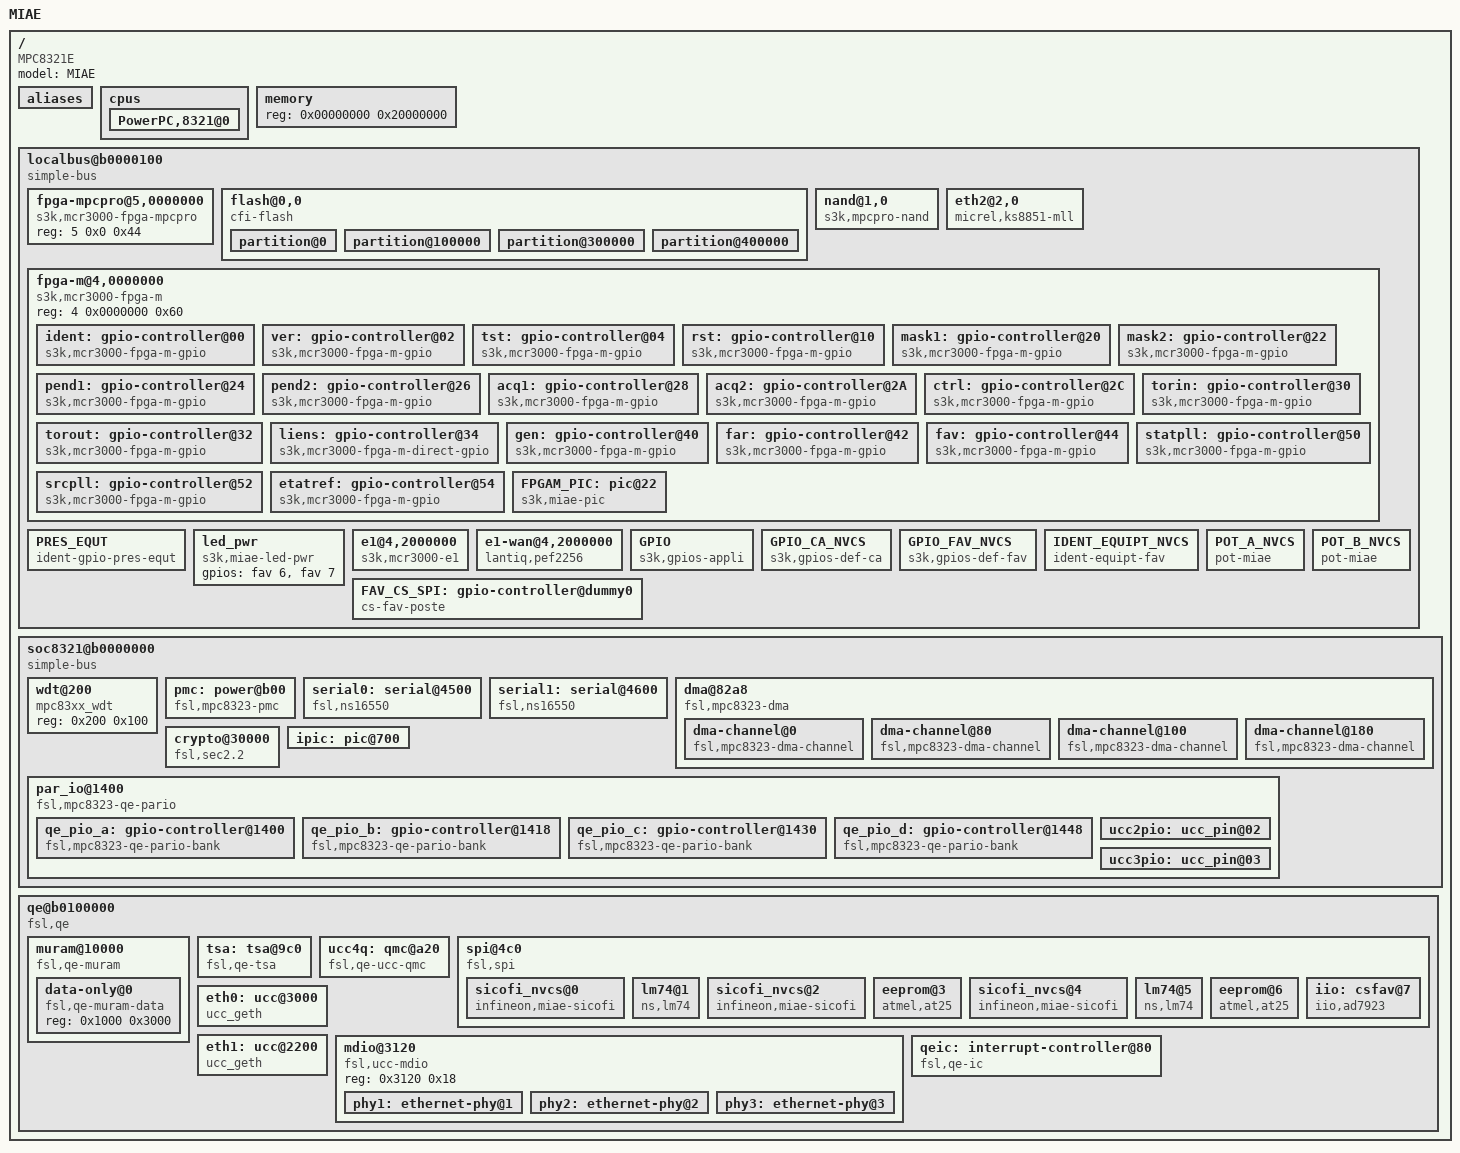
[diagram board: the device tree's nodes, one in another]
/*
 * MPC8321E MIA ethernet Device Tree Source
 * FIXME : 
 * Copyright 2007 Freescale Semiconductor Inc.
 *
 * This program is free software; you can redistribute  it and/or modify it
 * under  the terms of  the GNU General  Public License as published by the
 * Free Software Foundation;  either version 2 of the  License, or (at your
 * option) any later version.
 */

/dts-v1/;

/ {
	model = "MIAE";
	compatible = "MPC8321E", "MPC8323ERDB", "MPC832xRDB", "MPC83xxRDB", "fsl,base", "fsl,mpcpro";
	#address-cells = <1>;
	#size-cells = <1>;

	aliases {
		ethernet0 = &eth1;
		ethernet1 = &eth0;
		serial0 = &serial0;
		serial1 = &serial1;
	};

	cpus {
		#address-cells = <1>;
		#size-cells = <0>;

		PowerPC,8321@0 {
			device_type = "cpu";
			reg = <0x0>;
			d-cache-line-size = <0x20>;	// 32 bytes
			i-cache-line-size = <0x20>;	// 32 bytes
			d-cache-size = <16384>;	// L1, 16K
			i-cache-size = <16384>;	// L1, 16K
			timebase-frequency = <0>;
			bus-frequency = <0>;
			clock-frequency = <0>;
		};
	};

	memory {
		device_type = "memory";
		reg = <0x00000000 0x20000000>;
	};

	localbus@b0000100 {
		#address-cells = <2>;
		#size-cells = <1>;
		device_type = "soc";
		compatible = "simple-bus";
		ranges = <0 0x0 0x40000000 0x04000000	// Boot Flash
			  1 0x0 0xa0000000 0x00008000	// Nand Flash
			  2 0x0 0x92000000 0x00008000	// Eth Face avant
			  3 0x0 0x83400000 0x00010000	// DPRAM (DSP)
			  4 0x0 0x80000000 0x10000000	// Periphs
			  5 0x0 0x90000000 0x10000000	// FPGA-MPCPRO
			  6 0x0 0x81800000 0x00008000	// mezzanine
			  7 0x0 0x80800000 0x00008000>;	// DSP
		reg = <0xb0000000 0x00000200>;
		bus-frequency = <0>;

		fpga-mpcpro@5,0000000 {
			#address-cells = <1>;
			#size-cells = <1>;
			compatible = "s3k,mcr3000-fpga-mpcpro";
			reg = <5 0x0 0x44>;
		};

		flash@0,0 {
			#address-cells = <1>;
			#size-cells = <1>;
			compatible = "cfi-flash";
			reg = <0x0 0x00000000 0x4000000>;
			bank-width = <2>;
			device-width = <2>;
			partition@0 {
				label = "boot";
				reg = <0x0 0x100000>;
			};
			partition@100000 {
				label = "other u-boot";
				reg = <0x100000 0x200000>;
			};
			partition@300000 {
				label = "dtb";
				reg = <0x300000 0x100000>;
			};
			partition@400000 {
				label = "kernel";
				reg = <0x400000 0x400000>;
			};
		};

		nand@1,0 {
			compatible = "s3k,mpcpro-nand";
			reg = <1 0x0 0x01>;
			#address-cells = <1>;
			#size-cells = <1>;
			gpios = <&qe_pio_c 24 1 	// RDY
				 0			// nCE, we use chip select
				 &qe_pio_c 26 1		// ALE
				 &qe_pio_c 25 1		// CLE
				 0>;			// nwp
			//partition@0 {
			//	label = "mpcpro-nand";
			//	reg = <0x0 0x4000>;
			//};
		};

		eth2@2,0 {
			compatible = "micrel,ks8851-mll";
			reg =  <2 0x00 0xff
				2 0x100 0xff>;
			interrupts = <21 0x8>;
			interrupt-parent = <&ipic>;
		};

		fpga-m@4,0000000 { // Driver LDB (deviendra peut etre obsolete)
			#address-cells = <1>;
			#size-cells = <1>;
			compatible = "s3k,mcr3000-fpga-m";
			reg = <4 0x0000000 0x60>;
			ranges = <0 4 0x0000000 0x60>;
			ident: gpio-controller@00 {
				#gpio-cells = <2>;
				compatible = "s3k,mcr3000-fpga-m-gpio";
				reg = <0x00 2>;
				gpio-controller;
			};
			ver: gpio-controller@02 {
				#gpio-cells = <2>;
				compatible = "s3k,mcr3000-fpga-m-gpio";
				reg = <0x02 2>;
				gpio-controller;
			};
			tst: gpio-controller@04 {
				#gpio-cells = <2>;
				compatible = "s3k,mcr3000-fpga-m-gpio";
				reg = <0x04 2>;
				gpio-controller;
			};
			rst: gpio-controller@10 {
				#gpio-cells = <2>;
				compatible = "s3k,mcr3000-fpga-m-gpio";
				reg = <0x10 2>;
				gpio-controller;
			};
			mask1: gpio-controller@20 {
				#gpio-cells = <2>;
				compatible = "s3k,mcr3000-fpga-m-gpio";
				reg = <0x20 2>;
				gpio-controller;
			};
			mask2: gpio-controller@22 {
				#gpio-cells = <2>;
				compatible = "s3k,mcr3000-fpga-m-gpio";
				reg = <0x22 2>;
				gpio-controller;
			};
			pend1: gpio-controller@24 {
				#gpio-cells = <2>;
				compatible = "s3k,mcr3000-fpga-m-gpio";
				reg = <0x24 2>;
				gpio-controller;
			};
			pend2: gpio-controller@26 {
				#gpio-cells = <2>;
				compatible = "s3k,mcr3000-fpga-m-gpio";
				reg = <0x26 2>;
				gpio-controller;
			};
			acq1: gpio-controller@28 {
				#gpio-cells = <2>;
				compatible = "s3k,mcr3000-fpga-m-gpio";
				reg = <0x28 2>;
				gpio-controller;
			};
			acq2: gpio-controller@2A {
				#gpio-cells = <2>;
				compatible = "s3k,mcr3000-fpga-m-gpio";
				reg = <0x2A 2>;
				gpio-controller;
			};
			ctrl: gpio-controller@2C {
				#gpio-cells = <2>;
				compatible = "s3k,mcr3000-fpga-m-gpio";
				reg = <0x2C 2>;
				gpio-controller;
			};
			torin: gpio-controller@30 {
				#gpio-cells = <2>;
				compatible = "s3k,mcr3000-fpga-m-gpio";
				reg = <0x30 2>;
				interrupts = <255 255 255 255 255 5 6 7 8 9 10 11 12 13 14 15>;
				interrupt-parent = <&FPGAM_PIC>;
				gpio-controller;
			};
			torout: gpio-controller@32 {
				#gpio-cells = <2>;
				compatible = "s3k,mcr3000-fpga-m-gpio";
				reg = <0x32 2>;
				gpio-controller;
			};
			liens: gpio-controller@34 {
				#gpio-cells = <2>;
				compatible = "s3k,mcr3000-fpga-m-direct-gpio";
				reg = <0x34 2>;
				gpio-controller;
			};
			gen: gpio-controller@40 {
				#gpio-cells = <2>;
				compatible = "s3k,mcr3000-fpga-m-gpio";
				reg = <0x40 2>;
				gpio-controller;
			};
			far: gpio-controller@42 {
				#gpio-cells = <2>;
				compatible = "s3k,mcr3000-fpga-m-gpio";
				reg = <0x42 2>;
				interrupts = <255 255 255 255 255 255 255 255 255 255 255 0 28 30 29 31>;
				interrupt-parent = <&FPGAM_PIC>;
				gpio-controller;
			};
			fav: gpio-controller@44 {
				#gpio-cells = <2>;
				compatible = "s3k,mcr3000-fpga-m-gpio";
				reg = <0x44 2>;
				interrupts = <255 255 255 255 255 255 255 255 17 25 19 27 16 24 18 26>;
				interrupt-parent = <&FPGAM_PIC>;
				gpio-controller;
			};
			statpll: gpio-controller@50 {
				#gpio-cells = <2>;
				compatible = "s3k,mcr3000-fpga-m-gpio";
				reg = <0x50 2>;
				gpio-controller;
			};
			srcpll: gpio-controller@52 {
				#gpio-cells = <2>;
				compatible = "s3k,mcr3000-fpga-m-gpio";
				reg = <0x52 2>;
				gpio-controller;
			};
			etatref: gpio-controller@54 {
				#gpio-cells = <2>;
				compatible = "s3k,mcr3000-fpga-m-gpio";
				reg = <0x54 2>;
				gpio-controller;
			};
			FPGAM_PIC: pic@22 {
				interrupt-controller;
				#address-cells = <0>;
				#interrupt-cells = <1>;
				interrupts = <19 0>;
				interrupt-parent = <&ipic>;
				reg = <0x00 0x60>;	/* Mappage registres FPGAM */
				compatible = "s3k,miae-pic";
			};
		};

		PRES_EQUT {
			compatible = "ident-gpio-pres-equt";
			interrupts = <17 19 16 18>;	/* Equipt 1 et 2 */
			interrupt-parent = <&FPGAM_PIC>;
			reg = <4 0x44 2>;
			gpios = <&fav   8 1	/* Presence µCasque1 */
				&fav   10 1	/* Presence µMain1 */
				&fav   12 1	/* Presence µCasque2 */
				&fav   14 1>;	/* Presence µMain2 */
		};

		led_pwr {
			compatible = "s3k,miae-led-pwr";
			gpios = <&fav 6 2	/* led multi verte */
				 &fav 7 0>;	/* led multi rouge */
		};

		e1@4,2000000 {
			#address-cells = <1>;
			#size-cells = <1>;
			compatible = "s3k,mcr3000-e1";
			reg = <4 0x2000000 0xFF>;
			interrupts = <20 0>;
			interrupt-parent = <&ipic>;
		};
		
		e1-wan@4,2000000 {
			#address-cells = <1>;
			#size-cells = <1>;
			compatible = "lantiq,pef2256";
			reg = <4 0x2000000 0xFF>;
			data-rate = <4>;
			interrupts = <20 0>;
			interrupt-parent = <&ipic>;
		};
		
		GPIO {
			/* 0 = sortie initialisee active */
			/* 1 = entree */
			/* 2 = sortie initialisee inactive */
			compatible = "s3k,gpios-appli";
			reg = <4 0x42 4>;
			gpios = <&torin   15 1	// TOR in 1
				&torin    14 1	// TOR in 2
				&torin    13 1	// TOR in 3
				&torin    12 1	// TOR in 4
				&torin    11 1	// TOR in 5
				&torin    10 1	// TOR in 6
				&torin     9 1	// TOR in 7
				&torin     8 1	// TOR in 8
				&torin     7 1	// TOR in 9
				&torin     6 1	// TOR in 10
				&torin     5 1	// TOR in 11
				&torout   15 2	// TOR out 1
				&torout   14 2	// TOR out 2
				&torout   13 2	// TOR out 3
				&torout   12 2	// TOR out 4
				&torout   11 2	// TOR out 5
				&torout   10 2	// TOR out 6
				&torout    9 2	// TOR out 7
				&torout    8 2	// TOR out 8
				&far      15 1	// BP Alt
				&far      13 1	// Alternat 1
				&far      14 1	// Alternat 2
				&far      12 1	// Alternat Combine
				&far      11 1	// Presence Combine
				&fav      11 1	// Alternat µMain1
				&fav      15 1	// Alternat µMain2
				&fav       9 1	// Alternat µCasque1
				&fav      13 1>;	// Alternat µCasque2
		};

/*		GPIO_CA_CLA {
			compatible = "s3k,gpios-def-ca", "cs,mia-far";
			far-id = <0 7>;
			names = "tor_in_1",
				"tor_in_2",
				"tor_in_3",
				"tor_in_4",
				"tor_in_5",
				"tor_in_6",
				"tor_in_7",
				"tor_in_8",
				"tor_in_9",
				"tor_in_10",
				"tor_in_11",
				"tor_out_1",
				"tor_out_2",
				"tor_out_3",
				"tor_out_4",
				"tor_out_5",
				"tor_out_6",
				"tor_out_7",
				"tor_out_8",
				"alt_bp",
				"tor_in_13",		// Alternat 1
				"tor_in_14",		// Alternat 2
				"alt_ucomb",
				"pres_ucomb";
			codec = "Rec. In 1",
				"Interco In 1",
				"Rec. In 2",
				"Interco In 2",
				"Micro ITH",
				"Audio OPT 1",
				"Audio OPT 2",
				"Micro Combine",
				"Rec. Out 1",
				"Interco Out 1",
				"Rec. Out 2",
				"Interco Out 2",
				"HP ITH",
				"HP 1",
				"HP 2",
				"Ecoute Combine";
		};

		GPIO_FAV_CLA {
			compatible = "s3k,gpios-def-fav", "cs,mia-fav";
			fav-id = <7>;
			names = "alt_umain_a",
				"alt_umain_b",
				"alt_ucasque_a",
				"alt_ucasque_b";
			pres  = "pres_ucasque_a",
				"pres_umain_a",
				"pres_ucasque_b",
				"pres_umain_b";
			codec = "Micro Casque_a",
				"Micro Main_a",
				"Micro Casque_b",
				"Micro Main_b",
				"Ec. droite Casque_a",
				"Ec. gauche Casque_a",
				"Ec. droite Casque_b",
				"Ec. gauche Casque_b";
		};
*/
		GPIO_CA_NVCS {
			compatible = "s3k,gpios-def-ca", "cs,mia-far";
			far-id = <1>;
			names = "tor_in_audio_1",
				"tor_in_audio_2",
				"tor_in_audio_3",
				"tor_in_audio_4",
				"tor_in_5",
				"alt_pedale_1",
				"alt_pedale_2",
				"dec_ucomb",
				"tor_in_9",
				"tor_in_10",
				"alt_aith",
				"tor_out_audio_1",
				"tor_out_audio_2",
				"tor_out_audio_3",
				"tor_out_audio_4",
				"tor_out_5",
				"tor_out_6",
				"none",
				"none",
				"alt_bp",
				"tor_in_13",		// Alternat 1
				"tor_in_14",		// Alternat 2
				"alt_ucomb",
				"pres_ucomb";
			codec = "Audio In 1",
				"Audio In 2",
				"Audio In 3",
				"Audio In 4",
				"Micro ITH",
				"Audio OPT 1",
				"Audio OPT 2",
				"Micro Combine",
				"Audio Out 1",
				"Audio Out 2",
				"Audio Out 3",
				"Audio Out 4",
				"Audio Out 5",
				"HP 1",
				"HP 2",
				"Ecoute Combine";
		};

		GPIO_FAV_NVCS {
			compatible = "s3k,gpios-def-fav", "cs,mia-fav";
			fav-id = <3 5 6>;
			names = "alt_umain_a",
				"alt_umain_b",
				"alt_ucasque_a",
				"alt_ucasque_b";
			pres  = "pres_ucasque_a",
				"pres_umain_a",
				"pres_ucasque_b",
				"pres_umain_b";
			codec = "Micro Casque_a",
				"Micro Main_a",
				"Micro Casque_b",
				"Micro Main_b",
				"Ec. droite Casque_a",
				"Ec. gauche Casque_a",
				"Ec. droite Casque_b",
				"Ec. gauche Casque_b";
		};
/*
		GPIO_CA_GW {
			compatible = "s3k,gpios-def-ca", "cs,mia-far";
			far-id = <4>;
			names = "tor_in_1",
				"tor_in_2",
				"tor_in_3",
				"tor_in_4",
				"tor_in_5",
				"tor_in_6",
				"tor_in_7",
				"none",
				"none",
				"dptt",
				"pt_ct",
				"tor_out_1",
				"tor_out_2",
				"tor_out_3",
				"tor_out_4",
				"tor_out_5",
				"tor_out_6",
				"tor_out_7",
				"cgc",
				"none",
				"none",
				"none",
				"none",
				"none";
			codec = "Audio In 1",
				"Audio In 2",
				"Audio In 3",
				"Audio In 4",
				"Audio In 5",
				"Audio In 6",
				"Audio In 7",
				"Audio In 8",
				"Audio Out 1",
				"Audio Out 2",
				"Audio Out 3",
				"Audio Out 4",
				"not used",
				"not used",
				"not used",
				"not used";
		};

		GPIO_FAV_GW {
			compatible = "s3k,gpios-def-fav", "cs,mia-fav";
			fav-id = <4>;
			names = "none",
				"none",
				"none",
				"none";
			pres  = "none",
				"none",
				"none",
				"none";
			codec = "Micro Casque_a",
				"not used",
				"not used",
				"not used",
				"Ec. droite Casque_a",
				"not used",
				"not used",
				"not used";
		};
*/		
		IDENT_EQUIPT_NVCS {
			compatible = "ident-equipt-fav", "cs,mia-fav";
			fav-id = <3 5 6>;
			infos = "22",	/* nombre d'équipements possibles */
				/* bornes min et max, niveaux in et out en dB, croissement TS, type casque */
				"0",	"340",	"-27",	"-10",	"no",	"yes",	/* equipement 1 */
				"341",	"420",	"-27",	"-10",	"no",	"yes",	/* equipement 2 */
				"421",	"502",	"-27",	"-10",	"no",	"yes",	/* equipement 3 */
				"503",	"578",	"-27",	"-10",	"no",	"yes",	/* equipement 4 */
				"579",	"682",	"-27",	"-10",	"no",	"yes",	/* equipement 5 */
				"683",	"804",	"-27",	"-10",	"no",	"yes",	/* equipement 6 */
				"805",	"908",	"-7",	"-17",	"yes",	"yes",	/* equipement 7 */
				"909",	"1016",	"-27",	"-10",	"no",	"yes",	/* equipement 8 */
				"1017",	"1120",	"-27",	"-10",	"no",	"yes",	/* equipement 9 */
				"1121",	"1232",	"-27",	"-10",	"no",	"yes",	/* equipement 10 */
				"1233",	"1392",	"-27",	"-10",	"no",	"yes",	/* equipement 11 */
				"1393",	"1523",	"-23",	"-1",	"no",	"yes",	/* equipement 12 */
				"1524",	"1664",	"-27",	"-10",	"no",	"yes",	/* equipement 13 */
				"1665",	"1786",	"-27",	"-10",	"no",	"yes",	/* equipement 14 */
				"1787",	"1954",	"-27",	"-10",	"no",	"yes",	/* equipement 15 */
				"1955",	"2194",	"-27",	"-10",	"no",	"yes",	/* equipement 16 */
				"2195",	"2396",	"-27",	"-10",	"no",	"yes",	/* equipement 17 */
				"2397",	"2556",	"-27",	"-10",	"no",	"yes",	/* equipement 18 */
				"2557",	"2738",	"-27",	"-10",	"no",	"yes",	/* equipement 19 */
				"2739",	"2966",	"-27",	"-10",	"no",	"yes",	/* equipement 20 */
				"2967",	"3156",	"-11",	"-10",	"no",	"no",	/* equipement 21 */
				"3157",	"4095",	"-27",	"-10",	"no",	"yes";	/* sans equipement */
		};

		FAV_CS_SPI: gpio-controller@dummy0 {
			#gpio-cells = <2>;
			compatible = "cs-fav-poste";
			gpio-controller;
			reg = <4 0x44 2>;
			gpios = <&fav 5 1	/* CS FAV */
				 &fav 4 1	/* CS Ident equipement */
				 &fav 3 1>;	/* CS FPGA */
		};
		
		POT_A_NVCS {
			compatible = "pot-miae", "cs,mia-fav";
			fav-id = <5 6>;
			user-name = "pot_a";
			dev-name = "ad7923";
			io-channels = <&iio 0>;
			io-channel-names = "channel_0";
			dev-channel = "channel_0";
		};
		POT_B_NVCS {
			compatible = "pot-miae", "cs,mia-fav";
			fav-id = <5 6>;
			user-name = "pot_b";
			dev-name = "ad7923";
			io-channels = <&iio 1>;
			io-channel-names = "channel_1";
			dev-channel = "channel_1";
		};
		
/*		POT_A_PO {
			compatible = "pot-miae", "cs,mia-fav";
			fav-id = <3>;
			user-name = "pot_a";
			dev-name = "none";
			dev-channel = "channel_0";
		};
		POT_B_PO {
			compatible = "pot-miae", "cs,mia-fav";
			fav-id = <3>;
			user-name = "pot_b";
			dev-name = "none";
			dev-channel = "channel_1";
		};
		POT_C_PO {
			compatible = "pot-miae", "cs,mia-fav";
			fav-id = <3>;
			user-name = "pot_c";
			dev-name = "none";
			dev-channel = "channel_2";
		};
		POT_D_PO {
			compatible = "pot-miae", "cs,mia-fav";
			fav-id = <3>;
			user-name = "pot_d";
			dev-name = "none";
			dev-channel = "channel_3";
		};
*/	};

	soc8321@b0000000 {
		#address-cells = <1>;
		#size-cells = <1>;
		device_type = "soc";
		compatible = "simple-bus";
		ranges = <0x0 0xb0000000 0x00100000>;
		reg = <0xb0000000 0x00000200>;
		bus-frequency = <0>;
		
		wdt@200 {
			device_type = "watchdog";
			compatible = "mpc83xx_wdt";
			reg = <0x200 0x100>;
		};

		pmc: power@b00 {
			compatible = "fsl,mpc8323-pmc", "fsl,mpc8349-pmc";
			reg = <0xb00 0x100 0xa00 0x100>;
			interrupts = <80 0x8>;
			interrupt-parent = <&ipic>;
		};

		serial0: serial@4500 {
			cell-index = <0>;
			device_type = "serial";
			compatible = "fsl,ns16550", "ns16550";
			reg = <0x4500 0x100>;
			clock-frequency = <0>;
			interrupts = <9 0x8>;
			interrupt-parent = <&ipic>;
		};

		serial1: serial@4600 {
			cell-index = <1>;
			device_type = "serial";
			compatible = "fsl,ns16550", "ns16550";
			reg = <0x4600 0x100>;
			clock-frequency = <0>;
			interrupts = <10 0x8>;
			interrupt-parent = <&ipic>;
		};

		dma@82a8 {
			#address-cells = <1>;
			#size-cells = <1>;
			compatible = "fsl,mpc8323-dma", "fsl,elo-dma";
			reg = <0x82a8 4>;
			ranges = <0 0x8100 0x1a8>;
			interrupt-parent = <&ipic>;
			interrupts = <71 8>;
			cell-index = <0>;
			dma-channel@0 {
				compatible = "fsl,mpc8323-dma-channel", "fsl,elo-dma-channel";
				reg = <0 0x80>;
				cell-index = <0>;
				interrupt-parent = <&ipic>;
				interrupts = <71 8>;
			};
			dma-channel@80 {
				compatible = "fsl,mpc8323-dma-channel", "fsl,elo-dma-channel";
				reg = <0x80 0x80>;
				cell-index = <1>;
				interrupt-parent = <&ipic>;
				interrupts = <71 8>;
			};
			dma-channel@100 {
				compatible = "fsl,mpc8323-dma-channel", "fsl,elo-dma-channel";
				reg = <0x100 0x80>;
				cell-index = <2>;
				interrupt-parent = <&ipic>;
				interrupts = <71 8>;
			};
			dma-channel@180 {
				compatible = "fsl,mpc8323-dma-channel", "fsl,elo-dma-channel";
				reg = <0x180 0x28>;
				cell-index = <3>;
				interrupt-parent = <&ipic>;
				interrupts = <71 8>;
			};
		};

		crypto@30000 {
			compatible = "fsl,sec2.2", "fsl,sec2.1", "fsl,sec2.0";
			reg = <0x30000 0x10000>;
			interrupts = <11 0x8>;
			interrupt-parent = <&ipic>;
			fsl,num-channels = <1>;
			fsl,channel-fifo-len = <24>;
			fsl,exec-units-mask = <0x4c>;
			fsl,descriptor-types-mask = <0x0122003f>;
			sleep = <&pmc 0x03000000>;
		};

		ipic:pic@700 {
			interrupt-controller;
			#address-cells = <0>;
			#interrupt-cells = <2>;
			reg = <0x700 0x100>;
			device_type = "ipic";
		};

		par_io@1400 {
			#address-cells = <1>;
			#size-cells = <1>;
			reg = <0x1400 0x100>;
			ranges = < 0 0 0xb0001400 0x18
				   1 0 0xb0001418 0x18
				   2 0 0xb0001430 0x18
				   3 0 0xb0001448 0x18>;
			compatible = "fsl,mpc8323-qe-pario";
			device_type = "par_io";
			num-ports = <7>;

			qe_pio_a: gpio-controller@1400 {
				#gpio-cells = <2>;
				compatible = "fsl,mpc8323-qe-pario-bank";
				reg = <0x1400 0x18>;
				gpio-controller;
			};

			qe_pio_b: gpio-controller@1418 {
				#gpio-cells = <2>;
				compatible = "fsl,mpc8323-qe-pario-bank";
				reg = <0x1418 0x18>;
				gpio-controller;
			};

			qe_pio_c: gpio-controller@1430 {
				#gpio-cells = <2>;
				compatible = "fsl,mpc8323-qe-pario-bank";
				reg = <0x1430 0x18>;
				gpio-controller;
			};

			qe_pio_d: gpio-controller@1448 {
				#gpio-cells = <2>;
				compatible = "fsl,mpc8323-qe-pario-bank";
				reg = <0x1448 0x18>;
				gpio-controller;
			};

			ucc2pio:ucc_pin@02 {
				pio-map = <
			/* port  pin  dir  open_drain  assignment  has_irq */
				3  4  3  0  2  0 	/* MDIO */
				3  5  1  0  2  0 	/* MDC */

				0 18  1  0  1  0	/* R1_TXD0 */
				0 19  1  0  1  0	/* R1_TXD1 */
				0 22  2  0  1  0	/* R1_RXD0 */
				0 23  2  0  1  0	/* R1_RXD1 */
				0 30  1  0  1  0	/* R1_TXEN */
				0 28  2  0  1  0	/* R1_CRS_DV */
				0 26  2  0  1  0	/* R1_RXER */
				3 10  2  0  3  0>;	/* R1_REF_CLK */
			};
			ucc3pio:ucc_pin@03 {
				pio-map = <
			/* port  pin  dir  open_drain  assignment  has_irq */
				1  0  1  0  1  0	/* R2_TXD0 */
				1  1  1  0  1  0	/* R2_TXD1 */
				1  4  2  0  1  0	/* R2_RXD0 */
				1  5  2  0  1  0	/* R2_RXD1 */
				1 12  1  0  1  0	/* R2_TXEN */
				1 10  2  0  1  0	/* R2_CRS_DV */
				1  8  2  0  1  0	/* R2_RXER */
				1 14  2  0  1  0>;	/* R2_REF_CLK */
			};
		};
	};

	qe@b0100000 {
		#address-cells = <1>;
		#size-cells = <1>;
		device_type = "qe";
		compatible = "fsl,qe";
		ranges = <0x0 0xb0100000 0x00100000>;
		reg = <0xb0100000 0x480>;
		brg-frequency = <0>;
		bus-frequency = <198000000>;
		fsl,qe-num-riscs = <1>;
		fsl,qe-num-snums = <28>;

		muram@10000 {
 			#address-cells = <1>;
 			#size-cells = <1>;
			compatible = "fsl,qe-muram", "fsl,cpm-muram";
			ranges = <0x0 0x00010000 0x00004000>;

			/* conserver les 4 premiers Kbytes pour QMC */
			data-only@0 {
				compatible = "fsl,qe-muram-data",
					     "fsl,cpm-muram-data";
				reg = <0x1000 0x3000>;
			};
		};

		tsa: tsa@9c0 {
			compatible = "fsl,qe-tsa";
			reg = <0x9c0 0x1>;	/* necessaire mais non utilise */
			/* parametres possible : none, UCC4 */
			ucc_qmc_miae = "UCC4";
			/* vitesse bus numerique 4 ou 8 MHz */
			data_rate = <4>;
		};

		ucc4q: qmc@a20 {
			device_type = "qmc";
			compatible = "fsl,qe-ucc-qmc";
			cell-index = <4>;	/* The UCC number, 1-7*/
			reg = <0x3200 0x200 0x10000 0x1000>;
			interrupts = <35>;
			interrupt-parent = <&qeic>;
			clock-name = "clk1";
		};

		spi@4c0 {
			#address-cells = <1>;
			#size-cells = <0>;
			cell-index = <0>;
			compatible = "fsl,spi";
			reg = <0x4c0 0x40>;
			interrupts = <2>;
			interrupt-parent = <&qeic>;
			mode = "qe";
			     	/* port     pin cs-high */
			gpios =  <&qe_pio_b 16   1	/* SICOFI 1 */
				  &qe_pio_c  5   1	/* TEMP carte base */
				  &qe_pio_c 28   1	/* SICOFI 2 */
				  &qe_pio_d  3   1	/* EEPROM MPCPRO */
				  &qe_pio_c 23   1	/* SICOFI 3 */
				  &qe_pio_c  3   1	/* TEMP MPCPRO */
				  &qe_pio_c  2   1	/* EEPROM carte base */
				  &FAV_CS_SPI 0  1	/* FAV SPI */
				  &FAV_CS_SPI 2  1>;	/* FAV POSTE FPGA */

/*			sicofi@0 {
				compatible = "infineon,miae-sicofi", "cs,mia-far";
				far-id = <0 2 3 4 5 6 7>;
				spi-max-frequency = <1000000>;
				reg = <0>;
				spi-cs-high;
				spi-cpha;
				spi-troll;
				name_codec = "codec_1";
				analog_in = "-2dB -2dB -2dB -2dB";
				analog_out = "6dB 6dB 6dB 6dB";
				niveau_in = "-10dB -10dB -10dB -10dB";
				niveau_out = "-10dB -10dB -10dB -10dB";
			};
*/			sicofi_nvcs@0 {
				compatible = "infineon,miae-sicofi", "cs,mia-far";
				far-id = <1>;
				spi-max-frequency = <1000000>;
				reg = <0>;
				spi-cs-high;
				spi-cpha;
				spi-troll;
				name_codec = "codec_1";
				analog_in = "-2dB -2dB -2dB -2dB";
				analog_out = "0dB 0dB 0dB 0dB";
				niveau_in = "-10dB -10dB -10dB -10dB";
				niveau_out = "-10dB -10dB -10dB -10dB";
			};
			lm74@1 {
				compatible = "ns,lm74";
				spi-max-frequency = <1000000>;
				reg = <1>;
				spi-cs-high;
			};
//			sicofi@2 {
//				compatible = "infineon,miae-sicofi", "cs,mia-far";
//				far-id = <0 2 3 5 6 7>;
//				spi-max-frequency = <1000000>;
//				reg = <2>;
//				spi-cs-high;
//				spi-cpha;
//				spi-troll;
//				name_codec = "codec_2";
//				analog_in = "-2dB 0dB 0dB 12dB";
//				analog_out = "3dB 3dB 3dB 4,5dB";
//				niveau_in = "-10dB -10dB -10dB -31dB";
//				niveau_out = "-10dB -10dB -10dB -10dB";
//			};
			sicofi_nvcs@2 {
				compatible = "infineon,miae-sicofi", "cs,mia-far";
				far-id = <1>;
				spi-max-frequency = <1000000>;
				reg = <2>;
				spi-cs-high;
				spi-cpha;
				spi-troll;
				name_codec = "codec_2";
				analog_in = "-2dB 0dB 0dB 18dB";
				analog_out = "6dB 3dB 3dB 4,5dB";
				niveau_in = "-10dB -10dB -10dB -37dB";
				niveau_out = "-10dB -10dB -10dB -10dB";
			};
//			sicofi_gw@2 {
//				compatible = "infineon,miae-sicofi", "cs,mia-far";
//				far-id = <4>;
//				spi-max-frequency = <1000000>;
//				reg = <2>;
//				spi-cs-high;
//				spi-cpha;
//				spi-troll;
//				name_codec = "codec_2";
//				analog_in = "-3dB -3dB -3dB -3dB";
//				analog_out = "3dB 3dB 3dB 3dB";
//				niveau_in = "-10dB -10dB -10dB -10dB";
//				niveau_out = "-10dB -10dB -10dB -10dB";
//			};
			eeprom@3 {
				compatible = "atmel,at25", "cs,eeprom";
				spi-max-frequency = <1000000>;
				reg = <3>;
				spi-cs-high;
				at25,byte-len = <1024>;
				at25,addr-mode = <2>;
				at25,page-size = <32>;
			};
//			sicofi@4 {
//				compatible = "infineon,miae-sicofi", "cs,mia-fav";
//				fav-id = <0 1 2 4 7>;
//				spi-max-frequency = <1000000>;
//				reg = <4>;
//				spi-cs-high;
//				spi-cpha;
//				spi-troll;
//				name_codec = "codec_3";
//				analog_in = "12dB -7dB 12dB -7dB";
//				analog_out = "6dB 6dB 6dB 6dB";
//				niveau_in = "-27dB -8dB -27dB -8dB";
//				niveau_out = "-10dB -10dB -10dB -10dB";
//			};
			sicofi_nvcs@4 {
				compatible = "infineon,miae-sicofi", "cs,mia-fav";
				fav-id = <5 6>;
				spi-max-frequency = <1000000>;
				reg = <4>;
				spi-cs-high;
				spi-cpha;
				spi-troll;
				name_codec = "codec_3";
				analog_in = "12dB -7dB 12dB -7dB";
				analog_out = "6dB 6dB 6dB 6dB";
				niveau_in = "-27dB -8dB -27dB -8dB";
				niveau_out = "-10dB -10dB -10dB -10dB";
				io-channels = <&iio 2>, <&iio 3>;
				iio-name = "ad7923";
				io-channel-names = "channel_2", "channel_3";
				iio-channel = "channel_2", "channel_3";
			};
//			sicofi_postes@4 {
//				compatible = "infineon,miae-sicofi", "cs,mia-fav";
//				fav-id = <3>;
//				spi-max-frequency = <1000000>;
//				reg = <4>;
//				spi-cs-high;
//				spi-cpha;
//				spi-troll;
//				name_codec = "codec_3";
//				analog_in = "12dB -7dB 12dB -7dB";
//				analog_out = "6dB 6dB 6dB 6dB";
//				niveau_in = "-27dB -8dB -27dB -8dB";
//				niveau_out = "-10dB -10dB -10dB -10dB";
//				io-channels = <&iio 0>, <&iio 1>;
//				iio-name = "ad7923";
//				io-channel-names = "channel_0", "channel_1";
//				iio-channel = "channel_0", "channel_1";
//			};
			lm74@5 {
				compatible = "ns,lm74";
				spi-max-frequency = <1000000>;
				reg = <5>;
				spi-cs-high;
			};
			eeprom@6 {
				compatible = "atmel,at25", "cs,eeprom";
				spi-max-frequency = <1000000>;
				reg = <6>;
				spi-cs-high;
				at25,byte-len = <1024>;
				at25,addr-mode = <2>;
				at25,page-size = <32>;
			};
			iio: csfav@7 {
				compatible = "iio,ad7923", "cs,mia-fav";
				spi-max-frequency = <2000000>;
				reg = <7>;
				spi-cs-high;
				spi-cpol;
				fav-id = <3 5 6>;
				#io-channel-cells = <1>;
			};
//			gpiofav: csfavgw@7 {
//				compatible = "gpio,max7301", "cs,mia-fav";
//				spi-max-frequency = <2000000>;
//				reg = <7>;
//				spi-cs-high;
//				#gpio-cells = <2>;
//				gpio-controller;
//				fav-id = <4>;
//			};
//			csfavfpga@8 {
//				compatible = "cs,fpga-poste", "cs,mia-fav";
//				spi-max-frequency = <2000000>;
//				reg = <8>;
//				spi-cs-high;
//				fav-id = <3>;
//			};
                };

//		spi@500 {
//			cell-index = <1>;
//			compatible = "fsl,spi";
//			reg = <0x500 0x40>;
//			interrupts = <1>;
//			interrupt-parent = <&qeic>;
//			mode = "cpu";
//		};

		eth0: ucc@3000 {
			device_type = "network";
			compatible = "ucc_geth";
			cell-index = <2>;
			reg = <0x3000 0x200>;
			interrupts = <33>;
			interrupt-parent = <&qeic>;
			local-mac-address = [ 00 00 00 00 00 00 ];
			rx-clock-name = "clk17";
			tx-clock-name = "clk17";
			phy-handle = <&phy1>;
			pio-handle = <&ucc2pio>;
			phy-connection-type = "rmii";
		};

		eth1: ucc@2200 {
			device_type = "network";
			compatible = "ucc_geth";
			cell-index = <3>;
			reg = <0x2200 0x200>;
			interrupts = <34>;
			interrupt-parent = <&qeic>;
			local-mac-address = [ 00 00 00 00 00 00 ];
			rx-clock-name = "clk12";
			tx-clock-name = "clk12";
			phy-handle = <&phy3 &phy2>;
			pio-handle = <&ucc3pio>;
			phy-connection-type = "rmii";
		};

		mdio@3120 {
			#address-cells = <1>;
			#size-cells = <0>;
			reg = <0x3120 0x18>;
			compatible = "fsl,ucc-mdio";

			phy1:ethernet-phy@1 {
				interrupt-parent = <&ipic>;
				reg = <0x1>;
				device_type = "ethernet-phy";
			};
			phy2:ethernet-phy@2 {
				interrupt-parent = <&ipic>;
				reg = <0x2>;	
				device_type = "ethernet-phy";
			};
			phy3:ethernet-phy@3 {
				interrupt-parent = <&ipic>;
				reg = <0x3>;	
				device_type = "ethernet-phy";
			};
		};

		qeic:interrupt-controller@80 {
			interrupt-controller;
			compatible = "fsl,qe-ic";
			#address-cells = <0>;
			#interrupt-cells = <1>;
			reg = <0x80 0x80>;
			big-endian;
			interrupts = <32 0x8 33 0x8>; //high:32 low:33
			interrupt-parent = <&ipic>;
		};
	};
};
